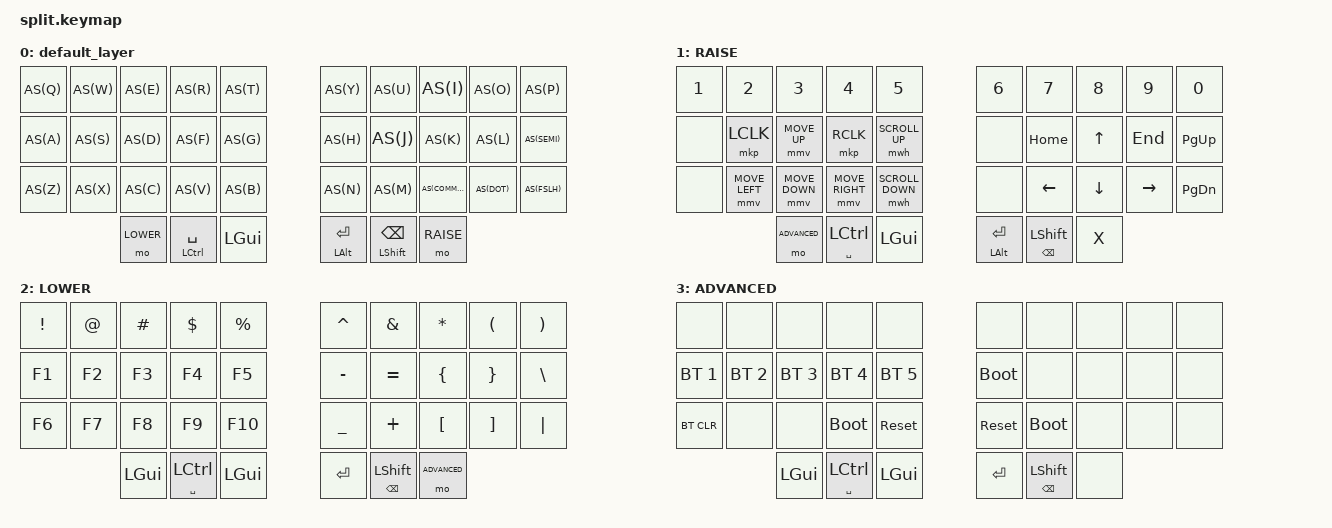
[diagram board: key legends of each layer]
/*
 * Copyright (c) 2020 The ZMK Contributors
 *
 * SPDX-License-Identifier: MIT
 */

#include <behaviors.dtsi>
#include <dt-bindings/zmk/keys.h>
#include <dt-bindings/zmk/bt.h>
#include <dt-bindings/zmk/outputs.h>
#include <dt-bindings/zmk/mouse.h>


#define COMBO_TIMEOUT 30

#define U_MOUSE_MOVE_MAX 1400                     /* <--- New max speed setting (default: 600) */
#undef MOVE_UP
#undef MOVE_DOWN
#undef MOVE_LEFT
#undef MOVE_RIGHT
#define MOVE_UP MOVE_VERT(-U_MOUSE_MOVE_MAX)
#define MOVE_DOWN MOVE_VERT(U_MOUSE_MOVE_MAX)
#define MOVE_LEFT MOVE_HOR(-U_MOUSE_MOVE_MAX)
#define MOVE_RIGHT MOVE_HOR(U_MOUSE_MOVE_MAX)
#define DEFAULT 0
#define RAISE 1
#define LOWER 2
#define ADVANCED 3

#define AS(keycode) &as LS(keycode) keycode

&mt {tapping-term-ms = <200>;};

&mmv {
    time-to-max-speed-ms = <400>;
};

&mwh {
    acceleration-exponent=<1>;
};

&kscan0 {
	debounce-period = <30>;
	};

/ {
    combos {
        compatible = "zmk,combos";
        combo_slash {
            timeout-ms = <30>;
            key-positions = <28 29>;
            bindings = <&kp LS(SLASH)>;
        };
        combo_del {
            timeout-ms = <30>;
            key-positions = <8 9>;
            bindings = <&kp DEL>;
        };
        combo_esc {
            timeout-ms = <30>;
            key-positions = <0 1>;
            bindings = <&kp ESC>;
        };
        combo_tab {
            timeout-ms = <30>;
            key-positions = <10 11>;
            bindings = <&kp TAB>;
        };
        combo_capslock {
            timeout-ms = <30>;
            key-positions = <10 20>;
            bindings = <&kp CAPS>;
        };
        combo_sqt {
            timeout-ms = <30>;
            key-positions = <18 19>;
            bindings = <&kp SQT>;
        };
        combo_tilde {
            timeout-ms = <30>;
            key-positions = <17 18>;
            bindings = <&kp TILDE>;
        };
        combo_copy {
            timeout-ms = <30>;
            key-positions = <22 23>;
            bindings = <&kp LC(C)>;
        };
        combo_paste {
            timeout-ms = <30>;
            key-positions = <23 24>;
            bindings = <&kp LC(V)>;
        };
        combo_cut {
            timeout-ms = <30>;
            key-positions = <21 22>;
            bindings = <&kp LC(X)>;
        };
        combo_undo {
            timeout-ms = <30>;
            key-positions = <20 21>;
            bindings = <&kp LC(Z)>;
        };
        combo_next {
            timeout-ms = <30>;
            key-positions = <20 21 22>;
            bindings = <&kp LC(Y)>;
        };
    };
};
/ {
    behaviors {
        as: auto_shift {
            compatible = "zmk,behavior-hold-tap";
            label = "AUTO_SHIFT";
            #binding-cells = <2>;
            tapping_term_ms = <200>;
            quick_tap_ms = <0>;
            flavor = "tap-preferred";
            bindings = <&kp>, <&kp>;
        };
    };
};

/ {
   keymap {
        compatible = "zmk,keymap";

        default_layer {
           bindings = <
    AS(Q)  AS(W)  AS(E)  AS(R)        AS(T)    AS(Y)  AS(U)   AS(I)      AS(O)    AS(P)
    AS(A)  AS(S)  AS(D)  AS(F)        AS(G)    AS(H)  AS(J)   AS(K)      AS(L)    AS(SEMI)
    AS(Z)  AS(X)  AS(C)  AS(V)        AS(B)    AS(N)  AS(M)   AS(COMMA)  AS(DOT)  AS(FSLH)
                       &mo LOWER &mt LCTRL SPACE &kp LGUI    &mt LALT RET  &mt  LSHIFT  BSPC  &mo RAISE
                        >;
                };
        RAISE {
           bindings = <
   &kp N1  &kp N2  &kp N3  &kp N4  &kp N5            &kp N6 &kp N7  &kp N8     &kp N9   &kp N0
   &none  &mkp LCLK &mmv MOVE_UP &mkp RCLK &mwh SCROLL_UP                    &none &kp HOME  &kp UP &kp END   &kp PG_UP
   &none &mmv MOVE_LEFT &mmv MOVE_DOWN  &mmv MOVE_RIGHT &mwh SCROLL_DOWN                    &none &kp LEFT  &kp DOWN &kp RIGHT &kp PG_DN
        &mo ADVANCED  &mt SPACE LCTRL &kp LGUI                 &mt LALT RET  &mt BSPC LSHIFT   &kp X
                        >;
                };
        LOWER {
           bindings = <
   &kp EXCL &kp AT &kp HASH &kp DLLR &kp PRCNT   &kp CARET &kp AMPS  &kp ASTRK     &kp LPAR   &kp RPAR
   &kp F1 &kp F2 &kp F3 &kp F4 &kp F5            &kp MINUS &kp EQUAL  &kp LBRC &kp RBRC   &kp BSLH
   &kp F6 &kp F7 &kp F8 &kp F9 &kp F10           &kp UNDER &kp PLUS  &kp LBKT &kp RBKT &kp PIPE
        &kp LGUI &mt SPACE LCTRL &kp LGUI        &kp RET  &mt BSPC LSHIFT   &mo ADVANCED
                        >;
                };
        ADVANCED {
           bindings = <
   &none  &none  &none  &none  &none                           &none &none  &none    &none  &none
   &bt BT_SEL 1 &bt BT_SEL 2 &bt BT_SEL 3 &bt BT_SEL 4 &bt BT_SEL 5        &bootloader &none  &none &none   &none
   &bt BT_CLR &none  &none &bootloader &sys_reset                   &sys_reset &bootloader  &none &none &none
               &kp LGUI    &mt SPACE LCTRL &kp LGUI                 &kp RET  &mt BSPC LSHIFT   &none
                        >;
                };
               
        };
};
